# LRFDRFE32 register map
Vendor: Texas Instruments
Peripheral module from a debugger description file (folder CC27xxx10).
Registers are 32-bit, access per field, reset 0x0 unless marked. A register's access mark holds for its fields unless they carry their own. Offsets are as the file gives them; lines under a group give offsets from that group; [hi:lo] are bit positions; {n}, {i} and the like mark numbered series; 'fields as' and 'values as' point back to an identical list; <NAME> marks a mode.

## LRFDRFE32 (part 1 of 2)
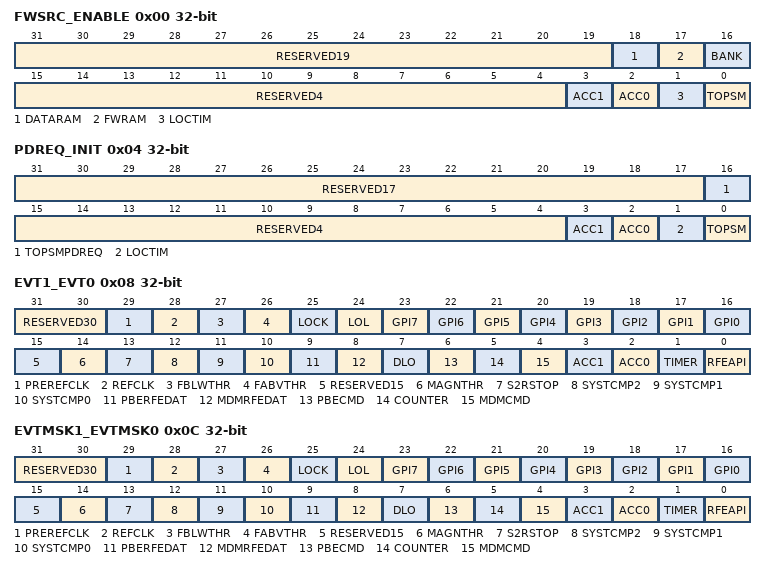
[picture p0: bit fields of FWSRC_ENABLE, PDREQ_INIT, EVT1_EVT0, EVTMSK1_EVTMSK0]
0x00 FWSRC_ENABLE — Internal. Only to be used through TI provided API.
  [31:19] RESERVED19 ro — Internal. Only to be used through TI provided API.
  [18] DATARAM rw — Internal. Only to be used through TI provided API.
    1=S2RRAM (Internal. Only to be used through TI provided API.); 0=RFERAM (Internal. Only to be used through TI provided API.)
  [17] FWRAM rw — Internal. Only to be used through TI provided API.
    values as DATARAM
  [16] BANK rw — Internal. Only to be used through TI provided API.
    1=ONE (Internal. Only to be used through TI provided API.); 0=ZERO (Internal. Only to be used through TI provided API.)
  [15:4] RESERVED4 ro — Internal. Only to be used through TI provided API.
  [3] ACC1 rw — Internal. Only to be used through TI provided API.
    1=EN (Internal. Only to be used through TI provided API.); 0=DIS (Internal. Only to be used through TI provided API.)
  [2] ACC0 rw — Internal. Only to be used through TI provided API.
    values as ACC1
  [1] LOCTIM rw — Internal. Only to be used through TI provided API.
    values as ACC1
  [0] TOPSM rw — Internal. Only to be used through TI provided API.
    values as ACC1
0x04 PDREQ_INIT — Internal. Only to be used through TI provided API.
  [31:17] RESERVED17 ro — Internal. Only to be used through TI provided API.
  [16] TOPSMPDREQ rw — Internal. Only to be used through TI provided API.
    values as FWSRC_ENABLE.BANK
  [15:4] RESERVED4 ro — Internal. Only to be used through TI provided API.
  [3] ACC1 wo — Internal. Only to be used through TI provided API.
    1=RESET (Internal. Only to be used through TI provided API.); 0=NO_EFFECT (Internal. Only to be used through TI provided API.)
  [2] ACC0 wo — Internal. Only to be used through TI provided API.
    values as ACC1
  [1] LOCTIM wo — Internal. Only to be used through TI provided API.
    values as ACC1
  [0] TOPSM wo — Internal. Only to be used through TI provided API.
    values as ACC1
0x08 EVT1_EVT0 ro — Internal. Only to be used through TI provided API.
  [31:30] RESERVED30 — Internal. Only to be used through TI provided API.
  [29] PREREFCLK — Internal. Only to be used through TI provided API.
    values as FWSRC_ENABLE.BANK
  [28] REFCLK — Internal. Only to be used through TI provided API.
    values as FWSRC_ENABLE.BANK
  [27] FBLWTHR — Internal. Only to be used through TI provided API.
    values as FWSRC_ENABLE.BANK
  [26] FABVTHR — Internal. Only to be used through TI provided API.
    values as FWSRC_ENABLE.BANK
  [25] LOCK — Internal. Only to be used through TI provided API.
    values as FWSRC_ENABLE.BANK
  [24] LOL — Internal. Only to be used through TI provided API.
    values as FWSRC_ENABLE.BANK
  [n+16] GPI{n} (n=0..7) — Internal. Only to be used through TI provided API.
    values as FWSRC_ENABLE.BANK
  [15] RESERVED15 — Internal. Only to be used through TI provided API.
  [14] MAGNTHR — Internal. Only to be used through TI provided API.
    values as FWSRC_ENABLE.BANK
  [13] S2RSTOP — Internal. Only to be used through TI provided API.
    values as FWSRC_ENABLE.BANK
  [12] SYSTCMP2 — Internal. Only to be used through TI provided API.
    values as FWSRC_ENABLE.BANK
  [11] SYSTCMP1 — Internal. Only to be used through TI provided API.
    values as FWSRC_ENABLE.BANK
  [10] SYSTCMP0 — Internal. Only to be used through TI provided API.
    values as FWSRC_ENABLE.BANK
  [9] PBERFEDAT — Internal. Only to be used through TI provided API.
    values as FWSRC_ENABLE.BANK
  [8] MDMRFEDAT — Internal. Only to be used through TI provided API.
    values as FWSRC_ENABLE.BANK
  [7] DLO — Internal. Only to be used through TI provided API.
    values as FWSRC_ENABLE.BANK
  [6] PBECMD — Internal. Only to be used through TI provided API.
    values as FWSRC_ENABLE.BANK
  [5] COUNTER — Internal. Only to be used through TI provided API.
    values as FWSRC_ENABLE.BANK
  [4] MDMCMD — Internal. Only to be used through TI provided API.
    values as FWSRC_ENABLE.BANK
  [3] ACC1 — Internal. Only to be used through TI provided API.
    values as FWSRC_ENABLE.BANK
  [2] ACC0 — Internal. Only to be used through TI provided API.
    values as FWSRC_ENABLE.BANK
  [1] TIMER — Internal. Only to be used through TI provided API.
    values as FWSRC_ENABLE.BANK
  [0] RFEAPI — Internal. Only to be used through TI provided API.
    values as FWSRC_ENABLE.BANK
0x0C EVTMSK1_EVTMSK0 — Internal. Only to be used through TI provided API.
  [31:30] RESERVED30 ro — Internal. Only to be used through TI provided API.
  [29] PREREFCLK rw — Internal. Only to be used through TI provided API.
    values as FWSRC_ENABLE.ACC1
  [28] REFCLK rw — Internal. Only to be used through TI provided API.
    values as FWSRC_ENABLE.ACC1
  [27] FBLWTHR rw — Internal. Only to be used through TI provided API.
    values as FWSRC_ENABLE.ACC1
  [26] FABVTHR rw — Internal. Only to be used through TI provided API.
    values as FWSRC_ENABLE.ACC1
  [25] LOCK rw — Internal. Only to be used through TI provided API.
    values as FWSRC_ENABLE.ACC1
  [24] LOL rw — Internal. Only to be used through TI provided API.
    values as FWSRC_ENABLE.ACC1
  [n+16] GPI{n} rw (n=0..7) — Internal. Only to be used through TI provided API.
    values as FWSRC_ENABLE.ACC1
  [15] RESERVED15 ro — Internal. Only to be used through TI provided API.
  [14] MAGNTHR rw — Internal. Only to be used through TI provided API.
    values as FWSRC_ENABLE.ACC1
  [13] S2RSTOP rw — Internal. Only to be used through TI provided API.
    values as FWSRC_ENABLE.ACC1
  [12] SYSTCMP2 rw — Internal. Only to be used through TI provided API.
    values as FWSRC_ENABLE.ACC1
  [11] SYSTCMP1 rw — Internal. Only to be used through TI provided API.
    values as FWSRC_ENABLE.ACC1
  [10] SYSTCMP0 rw — Internal. Only to be used through TI provided API.
    values as FWSRC_ENABLE.ACC1
  [9] PBERFEDAT rw — Internal. Only to be used through TI provided API.
    values as FWSRC_ENABLE.ACC1
  [8] MDMRFEDAT rw — Internal. Only to be used through TI provided API.
    values as FWSRC_ENABLE.ACC1
  [7] DLO rw — Internal. Only to be used through TI provided API.
    values as FWSRC_ENABLE.ACC1
  [6] PBECMD rw — Internal. Only to be used through TI provided API.
    values as FWSRC_ENABLE.ACC1
  [5] COUNTER rw — Internal. Only to be used through TI provided API.
    values as FWSRC_ENABLE.ACC1
  [4] MDMCMD rw — Internal. Only to be used through TI provided API.
    values as FWSRC_ENABLE.ACC1
  [3] ACC1 rw — Internal. Only to be used through TI provided API.
    values as FWSRC_ENABLE.ACC1
  [2] ACC0 rw — Internal. Only to be used through TI provided API.
    values as FWSRC_ENABLE.ACC1
  [1] TIMER rw — Internal. Only to be used through TI provided API.
    values as FWSRC_ENABLE.ACC1
  [0] RFEAPI rw — Internal. Only to be used through TI provided API.
    values as FWSRC_ENABLE.ACC1
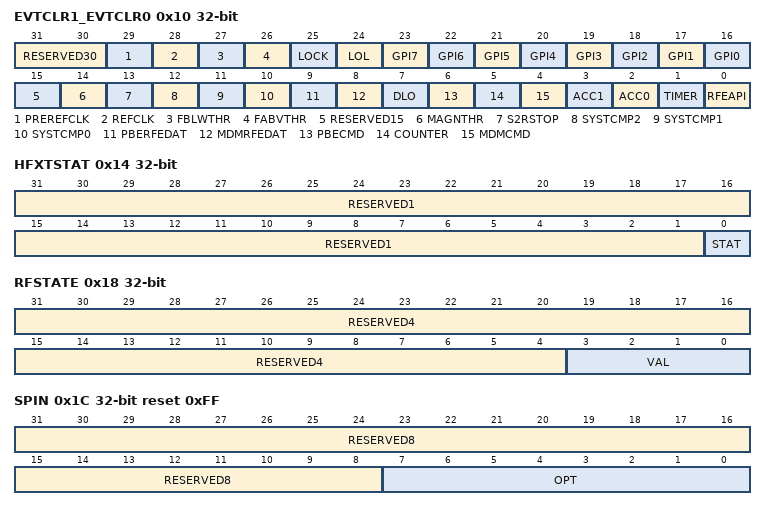
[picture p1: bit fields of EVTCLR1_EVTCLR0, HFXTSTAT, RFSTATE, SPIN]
0x10 EVTCLR1_EVTCLR0 — Internal. Only to be used through TI provided API.
  [31:30] RESERVED30 ro — Internal. Only to be used through TI provided API.
  [29] PREREFCLK wo — Internal. Only to be used through TI provided API.
    values as FWSRC_ENABLE.BANK
  [28] REFCLK wo — Internal. Only to be used through TI provided API.
    values as FWSRC_ENABLE.BANK
  [27] FBLWTHR wo — Internal. Only to be used through TI provided API.
    values as FWSRC_ENABLE.BANK
  [26] FABVTHR wo — Internal. Only to be used through TI provided API.
    values as FWSRC_ENABLE.BANK
  [25] LOCK wo — Internal. Only to be used through TI provided API.
    values as FWSRC_ENABLE.BANK
  [24] LOL wo — Internal. Only to be used through TI provided API.
    values as FWSRC_ENABLE.BANK
  [n+16] GPI{n} wo (n=0..7) — Internal. Only to be used through TI provided API.
    values as FWSRC_ENABLE.BANK
  [15] RESERVED15 ro — Internal. Only to be used through TI provided API.
  [14] MAGNTHR wo — Internal. Only to be used through TI provided API.
    values as FWSRC_ENABLE.BANK
  [13] S2RSTOP wo — Internal. Only to be used through TI provided API.
    values as FWSRC_ENABLE.BANK
  [12] SYSTCMP2 wo — Internal. Only to be used through TI provided API.
    values as FWSRC_ENABLE.BANK
  [11] SYSTCMP1 wo — Internal. Only to be used through TI provided API.
    values as FWSRC_ENABLE.BANK
  [10] SYSTCMP0 wo — Internal. Only to be used through TI provided API.
    values as FWSRC_ENABLE.BANK
  [9] PBERFEDAT wo — Internal. Only to be used through TI provided API.
    values as FWSRC_ENABLE.BANK
  [8] MDMRFEDAT wo — Internal. Only to be used through TI provided API.
    values as FWSRC_ENABLE.BANK
  [7] DLO wo — Internal. Only to be used through TI provided API.
    values as FWSRC_ENABLE.BANK
  [6] PBECMD wo — Internal. Only to be used through TI provided API.
    values as FWSRC_ENABLE.BANK
  [5] COUNTER wo — Internal. Only to be used through TI provided API.
    values as FWSRC_ENABLE.BANK
  [4] MDMCMD wo — Internal. Only to be used through TI provided API.
    values as FWSRC_ENABLE.BANK
  [3] ACC1 wo — Internal. Only to be used through TI provided API.
    values as FWSRC_ENABLE.BANK
  [2] ACC0 wo — Internal. Only to be used through TI provided API.
    values as FWSRC_ENABLE.BANK
  [1] TIMER wo — Internal. Only to be used through TI provided API.
    values as FWSRC_ENABLE.BANK
  [0] RFEAPI wo — Internal. Only to be used through TI provided API.
    values as FWSRC_ENABLE.BANK
0x14 HFXTSTAT ro — Internal. Only to be used through TI provided API.
  [31:1] RESERVED1 — Internal. Only to be used through TI provided API.
  [0] STAT — Internal. Only to be used through TI provided API.
    1=QUAL (Internal. Only to be used through TI provided API.); 0=NONQUAL (Internal. Only to be used through TI provided API.)
0x18 RFSTATE — Internal. Only to be used through TI provided API.
  [31:4] RESERVED4 ro — Internal. Only to be used through TI provided API.
  [3:0] VAL rw — Internal. Only to be used through TI provided API.
    3=RX (Internal. Only to be used through TI provided API.); 2=TX (Internal. Only to be used through TI provided API.); 1=SYNTH (Internal. Only to be used through TI provided API.); 0=IDLE (Internal. Only to be used through TI provided API.)
0x1C SPIN ro reset 0xFF — Internal. Only to be used through TI provided API.
  [31:8] RESERVED8 — Internal. Only to be used through TI provided API.
  [7:0] OPT — Internal. Only to be used through TI provided API.
    255=ALLONES (Internal. Only to be used through TI provided API.); 0=ALLZEROS (Internal. Only to be used through TI provided API.)
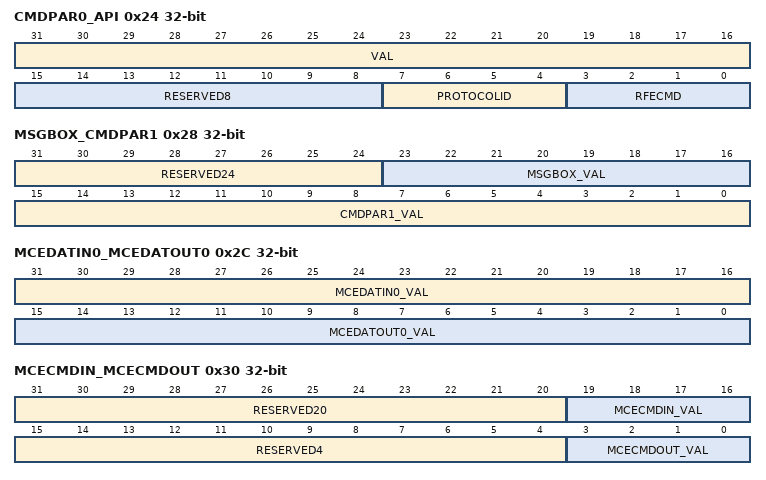
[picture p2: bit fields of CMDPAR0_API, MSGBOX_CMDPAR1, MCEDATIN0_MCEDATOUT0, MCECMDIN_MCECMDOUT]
0x24 CMDPAR0_API ro — Internal. Only to be used through TI provided API.
  [31:16] VAL — Internal. Only to be used through TI provided API.
    0xFFFF=ALLONES (Internal. Only to be used through TI provided API.); 0=ALLZEROS (Internal. Only to be used through TI provided API.)
  [15:8] RESERVED8 — Internal. Only to be used through TI provided API.
  [7:4] PROTOCOLID — Internal. Only to be used through TI provided API.
    15=ALLONES (Internal. Only to be used through TI provided API.); 0=ALLZEROS (Internal. Only to be used through TI provided API.)
  [3:0] RFECMD — Internal. Only to be used through TI provided API.
    values as PROTOCOLID
0x28 MSGBOX_CMDPAR1 — Internal. Only to be used through TI provided API.
  [31:24] RESERVED24 ro — Internal. Only to be used through TI provided API.
  [23:16] MSGBOX_VAL rw — Internal. Only to be used through TI provided API.
    values as SPIN.OPT
  [15:0] CMDPAR1_VAL ro — Internal. Only to be used through TI provided API.
    values as CMDPAR0_API.VAL
0x2C MCEDATIN0_MCEDATOUT0 — Internal. Only to be used through TI provided API.
  [31:16] MCEDATIN0_VAL ro — Internal. Only to be used through TI provided API.
    values as CMDPAR0_API.VAL
  [15:0] MCEDATOUT0_VAL rw — Internal. Only to be used through TI provided API.
    values as CMDPAR0_API.VAL
0x30 MCECMDIN_MCECMDOUT — Internal. Only to be used through TI provided API.
  [31:20] RESERVED20 ro — Internal. Only to be used through TI provided API.
  [19:16] MCECMDIN_VAL ro — Internal. Only to be used through TI provided API.
    values as CMDPAR0_API.PROTOCOLID
  [15:4] RESERVED4 ro — Internal. Only to be used through TI provided API.
  [3:0] MCECMDOUT_VAL rw — Internal. Only to be used through TI provided API.
    values as CMDPAR0_API.PROTOCOLID
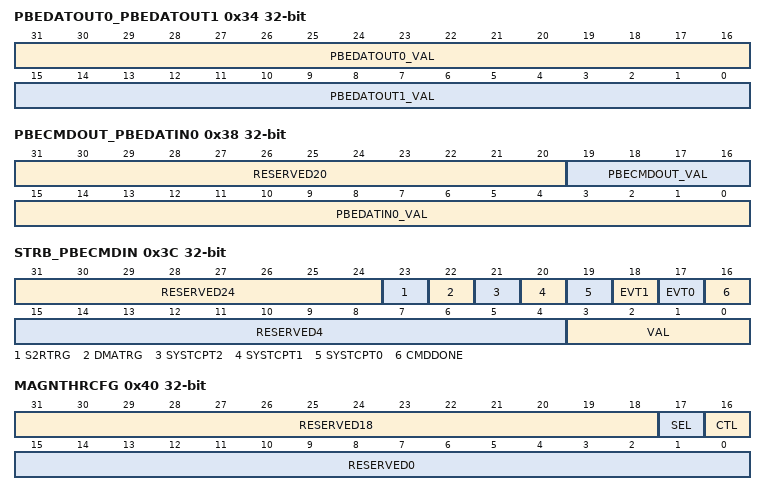
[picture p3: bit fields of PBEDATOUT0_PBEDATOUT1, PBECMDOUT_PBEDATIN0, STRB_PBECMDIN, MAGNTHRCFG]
0x34 PBEDATOUT0_PBEDATOUT1 rw — Internal. Only to be used through TI provided API.
  [31:16] PBEDATOUT0_VAL — Internal. Only to be used through TI provided API.
    values as CMDPAR0_API.VAL
  [15:0] PBEDATOUT1_VAL — Internal. Only to be used through TI provided API.
    values as CMDPAR0_API.VAL
0x38 PBECMDOUT_PBEDATIN0 — Internal. Only to be used through TI provided API.
  [31:20] RESERVED20 ro — Internal. Only to be used through TI provided API.
  [19:16] PBECMDOUT_VAL rw — Internal. Only to be used through TI provided API.
    values as CMDPAR0_API.PROTOCOLID
  [15:0] PBEDATIN0_VAL ro — Internal. Only to be used through TI provided API.
    values as CMDPAR0_API.VAL
0x3C STRB_PBECMDIN — Internal. Only to be used through TI provided API.
  [31:24] RESERVED24 ro — Internal. Only to be used through TI provided API.
  [23] S2RTRG wo — Internal. Only to be used through TI provided API.
    values as FWSRC_ENABLE.BANK
  [22] DMATRG wo — Internal. Only to be used through TI provided API.
    values as FWSRC_ENABLE.BANK
  [21] SYSTCPT2 wo — Internal. Only to be used through TI provided API.
    values as FWSRC_ENABLE.BANK
  [20] SYSTCPT1 wo — Internal. Only to be used through TI provided API.
    values as FWSRC_ENABLE.BANK
  [19] SYSTCPT0 wo — Internal. Only to be used through TI provided API.
    values as FWSRC_ENABLE.BANK
  [18] EVT1 wo — Internal. Only to be used through TI provided API.
    values as FWSRC_ENABLE.BANK
  [17] EVT0 wo — Internal. Only to be used through TI provided API.
    values as FWSRC_ENABLE.BANK
  [16] CMDDONE wo — Internal. Only to be used through TI provided API.
    1=YES (Internal. Only to be used through TI provided API.); 0=NO (Internal. Only to be used through TI provided API.)
  [15:4] RESERVED4 ro — Internal. Only to be used through TI provided API.
  [3:0] VAL ro — Internal. Only to be used through TI provided API.
    values as CMDPAR0_API.PROTOCOLID
0x40 MAGNTHRCFG — Internal. Only to be used through TI provided API.
  [31:18] RESERVED18 ro — Internal. Only to be used through TI provided API.
  [17] SEL rw — Internal. Only to be used through TI provided API.
    1=MAGNACC1 (Internal. Only to be used through TI provided API.); 0=MAGNACC0 (Internal. Only to be used through TI provided API.)
  [16] CTL rw — Internal. Only to be used through TI provided API.
    values as FWSRC_ENABLE.ACC1
  [15:0] RESERVED0 ro — Internal. Only to be used through TI provided API.
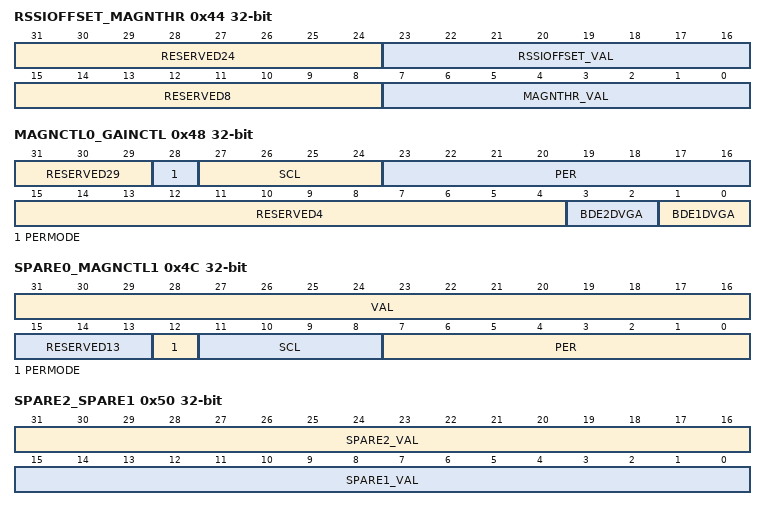
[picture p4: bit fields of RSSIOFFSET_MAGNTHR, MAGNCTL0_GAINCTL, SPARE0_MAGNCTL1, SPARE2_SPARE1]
0x44 RSSIOFFSET_MAGNTHR — Internal. Only to be used through TI provided API.
  [31:24] RESERVED24 ro — Internal. Only to be used through TI provided API.
  [23:16] RSSIOFFSET_VAL rw — Internal. Only to be used through TI provided API.
    values as SPIN.OPT
  [15:8] RESERVED8 ro — Internal. Only to be used through TI provided API.
  [7:0] MAGNTHR_VAL rw — Internal. Only to be used through TI provided API.
    values as SPIN.OPT
0x48 MAGNCTL0_GAINCTL — Internal. Only to be used through TI provided API.
  [31:29] RESERVED29 ro — Internal. Only to be used through TI provided API.
  [28] PERMODE rw — Internal. Only to be used through TI provided API.
    1=PERIODIC (Internal. Only to be used through TI provided API.); 0=ONESHOT (Internal. Only to be used through TI provided API.)
  [27:24] SCL rw — Internal. Only to be used through TI provided API.
    8=DIV256 (Internal. Only to be used through TI provided API.); 7=DIV128 (Internal. Only to be used through TI provided API.); 6=DIV64 (Internal. Only to be used through TI provided API.); 5=DIV32 (Internal. Only to be used through TI provided API.); 4=DIV16 (Internal. Only to be used through TI provided API.); 3=DIV8 (Internal. Only to be used through TI provided API.); 2=DIV4 (Internal. Only to be used through TI provided API.); 1=DIV2 (Internal. Only to be used through TI provided API.); 0=DIV1 (Internal. Only to be used through TI provided API.)
  [23:16] PER rw — Internal. Only to be used through TI provided API.
    values as SPIN.OPT
  [15:4] RESERVED4 ro — Internal. Only to be used through TI provided API.
  [3:2] BDE2DVGA rw — Internal. Only to be used through TI provided API.
    3=GAIN8 (Internal. Only to be used through TI provided API.); 2=GAIN4 (Internal. Only to be used through TI provided API.); 1=GAIN2 (Internal. Only to be used through TI provided API.); 0=GAIN1 (Internal. Only to be used through TI provided API.)
  [1:0] BDE1DVGA rw — Internal. Only to be used through TI provided API.
    values as BDE2DVGA
0x4C SPARE0_MAGNCTL1 — Internal. Only to be used through TI provided API.
  [31:16] VAL rw — Internal. Only to be used through TI provided API.
    values as CMDPAR0_API.VAL
  [15:13] RESERVED13 ro — Internal. Only to be used through TI provided API.
  [12] PERMODE rw — Internal. Only to be used through TI provided API.
    values as MAGNCTL0_GAINCTL.PERMODE
  [11:8] SCL rw — Internal. Only to be used through TI provided API.
    values as MAGNCTL0_GAINCTL.SCL
  [7:0] PER rw — Internal. Only to be used through TI provided API.
    values as SPIN.OPT
0x50 SPARE2_SPARE1 rw — Internal. Only to be used through TI provided API.
  [31:16] SPARE2_VAL — Internal. Only to be used through TI provided API.
    values as CMDPAR0_API.VAL
  [15:0] SPARE1_VAL — Internal. Only to be used through TI provided API.
    values as CMDPAR0_API.VAL
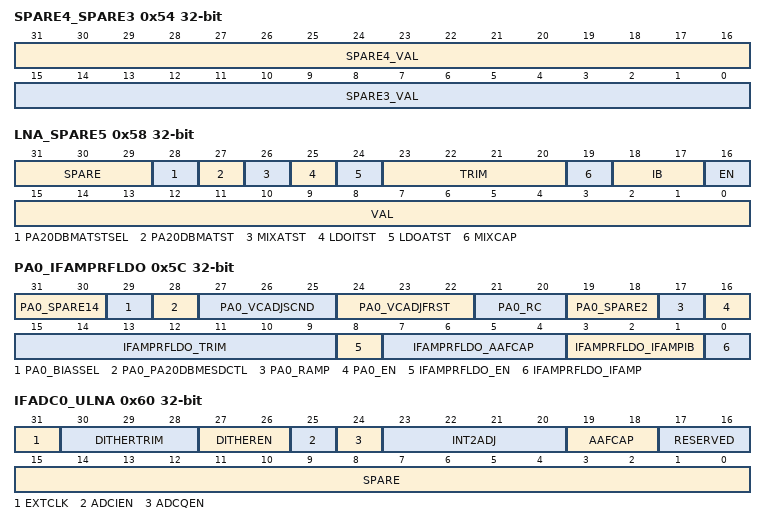
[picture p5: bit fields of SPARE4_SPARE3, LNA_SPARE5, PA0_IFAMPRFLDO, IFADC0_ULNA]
0x54 SPARE4_SPARE3 rw — Internal. Only to be used through TI provided API.
  [31:16] SPARE4_VAL — Internal. Only to be used through TI provided API.
    values as CMDPAR0_API.VAL
  [15:0] SPARE3_VAL — Internal. Only to be used through TI provided API.
    values as CMDPAR0_API.VAL
0x58 LNA_SPARE5 rw — Internal. Only to be used through TI provided API.
  [31:29] SPARE — Internal. Only to be used through TI provided API.
    values as FWSRC_ENABLE.ACC1
  [28] PA20DBMATSTSEL — Internal. Only to be used through TI provided API.
    1=SECOND (Internal. Only to be used through TI provided API.); 0=FIRST (Internal. Only to be used through TI provided API.)
  [27] PA20DBMATST — Internal. Only to be used through TI provided API.
    values as FWSRC_ENABLE.ACC1
  [26] MIXATST — Internal. Only to be used through TI provided API.
    values as FWSRC_ENABLE.ACC1
  [25] LDOITST — Internal. Only to be used through TI provided API.
    values as FWSRC_ENABLE.ACC1
  [24] LDOATST — Internal. Only to be used through TI provided API.
    values as FWSRC_ENABLE.ACC1
  [23:20] TRIM — Internal. Only to be used through TI provided API.
    15=ONES (Internal. Only to be used through TI provided API.); 0=ZEROS (Internal. Only to be used through TI provided API.)
  [19] MIXCAP — Internal. Only to be used through TI provided API.
    values as FWSRC_ENABLE.ACC1
  [18:17] IB — Internal. Only to be used through TI provided API.
    3=MAX (Internal. Only to be used through TI provided API.); 0=MIN (Internal. Only to be used through TI provided API.)
  [16] EN — Internal. Only to be used through TI provided API.
    1=ON (Internal. Only to be used through TI provided API.); 0=OFF (Internal. Only to be used through TI provided API.)
  [15:0] VAL — Internal. Only to be used through TI provided API.
    values as CMDPAR0_API.VAL
0x5C PA0_IFAMPRFLDO rw — Internal. Only to be used through TI provided API.
  [31:30] PA0_SPARE14 — Internal. Only to be used through TI provided API.
    values as LNA_SPARE5.IB
  [29] PA0_BIASSEL — Internal. Only to be used through TI provided API.
    values as FWSRC_ENABLE.BANK
  [28] PA0_PA20DBMESDCTL — Internal. Only to be used through TI provided API.
    values as FWSRC_ENABLE.BANK
  [27:25] PA0_VCADJSCND — Internal. Only to be used through TI provided API.
    7=MAX (Internal. Only to be used through TI provided API.); 0=MIN (Internal. Only to be used through TI provided API.)
  [24:22] PA0_VCADJFRST — Internal. Only to be used through TI provided API.
    values as PA0_VCADJSCND
  [21:20] PA0_RC — Internal. Only to be used through TI provided API.
    values as LNA_SPARE5.IB
  [19:18] PA0_SPARE2 — Internal. Only to be used through TI provided API.
    values as LNA_SPARE5.IB
  [17] PA0_RAMP — Internal. Only to be used through TI provided API.
    1=UP (Internal. Only to be used through TI provided API.); 0=DOWN (Internal. Only to be used through TI provided API.)
  [16] PA0_EN — Internal. Only to be used through TI provided API.
    values as FWSRC_ENABLE.ACC1
  [15:9] IFAMPRFLDO_TRIM — Internal. Only to be used through TI provided API.
    127=BYPASS (Internal. Only to be used through TI provided API.); 126=MAX (Internal. Only to be used through TI provided API.); 0=MIN (Internal. Only to be used through TI provided API.)
  [8] IFAMPRFLDO_EN — Internal. Only to be used through TI provided API.
    values as FWSRC_ENABLE.ACC1
  [7:4] IFAMPRFLDO_AAFCAP — Internal. Only to be used through TI provided API.
    15=MAX (Internal. Only to be used through TI provided API.); 0=MIN (Internal. Only to be used through TI provided API.)
  [3:1] IFAMPRFLDO_IFAMPIB — Internal. Only to be used through TI provided API.
    values as PA0_VCADJSCND
  [0] IFAMPRFLDO_IFAMP — Internal. Only to be used through TI provided API.
    values as FWSRC_ENABLE.ACC1
0x60 IFADC0_ULNA rw — Internal. Only to be used through TI provided API.
  [31] EXTCLK — Internal. Only to be used through TI provided API.
    values as FWSRC_ENABLE.ACC1
  [30:28] DITHERTRIM — Internal. Only to be used through TI provided API.
    7=ONES (Internal. Only to be used through TI provided API.); 0=ZEROS (Internal. Only to be used through TI provided API.)
  [27:26] DITHEREN — Internal. Only to be used through TI provided API.
    3=ENG (Internal. Only to be used through TI provided API.); 2=ENSD (Internal. Only to be used through TI provided API.); 1=ENS (Internal. Only to be used through TI provided API.); 0=DIS (Internal. Only to be used through TI provided API.)
  [25] ADCIEN — Internal. Only to be used through TI provided API.
    values as FWSRC_ENABLE.ACC1
  [24] ADCQEN — Internal. Only to be used through TI provided API.
    values as FWSRC_ENABLE.ACC1
  [23:20] INT2ADJ — Internal. Only to be used through TI provided API.
    values as LNA_SPARE5.TRIM
  [19:18] AAFCAP — Internal. Only to be used through TI provided API.
    values as DITHEREN
  [17:16] RESERVED — Internal. Only to be used through TI provided API.
    3=ONES (Internal. Only to be used through TI provided API.); 0=ZEROS (Internal. Only to be used through TI provided API.)
  [15:0] SPARE — Internal. Only to be used through TI provided API.
    values as CMDPAR0_API.VAL
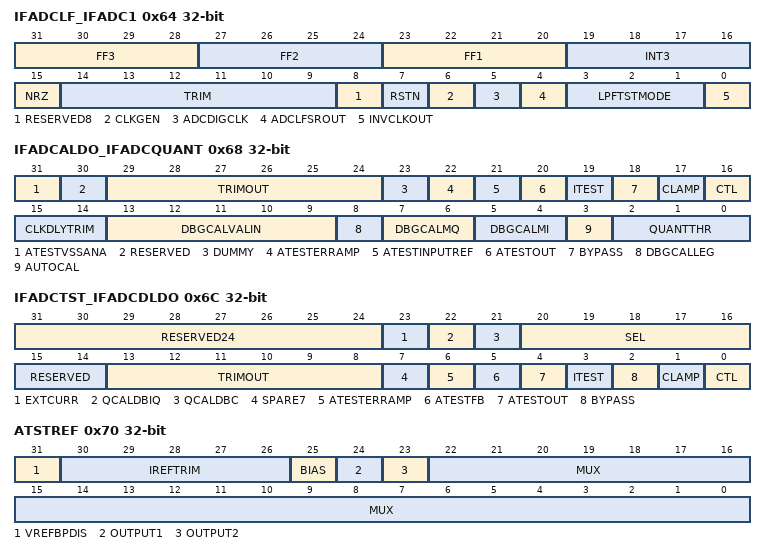
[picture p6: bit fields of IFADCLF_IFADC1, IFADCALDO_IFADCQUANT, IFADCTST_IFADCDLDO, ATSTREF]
0x64 IFADCLF_IFADC1 rw — Internal. Only to be used through TI provided API.
  [31:28] FF3 — Internal. Only to be used through TI provided API.
    values as LNA_SPARE5.TRIM
  [27:24] FF2 — Internal. Only to be used through TI provided API.
    values as LNA_SPARE5.TRIM
  [23:20] FF1 — Internal. Only to be used through TI provided API.
    values as LNA_SPARE5.TRIM
  [19:16] INT3 — Internal. Only to be used through TI provided API.
    values as LNA_SPARE5.TRIM
  [15] NRZ — Internal. Only to be used through TI provided API.
    values as FWSRC_ENABLE.ACC1
  [14:9] TRIM — Internal. Only to be used through TI provided API.
    63=ONES (Internal. Only to be used through TI provided API.); 0=ZEROS (Internal. Only to be used through TI provided API.)
  [8] RESERVED8 — Internal. Only to be used through TI provided API.
    values as FWSRC_ENABLE.ACC1
  [7] RSTN — Internal. Only to be used through TI provided API.
    1=DIS (Internal. Only to be used through TI provided API.); 0=EN (Internal. Only to be used through TI provided API.)
  [6] CLKGEN — Internal. Only to be used through TI provided API.
    values as FWSRC_ENABLE.ACC1
  [5] ADCDIGCLK — Internal. Only to be used through TI provided API.
    values as FWSRC_ENABLE.ACC1
  [4] ADCLFSROUT — Internal. Only to be used through TI provided API.
    values as FWSRC_ENABLE.ACC1
  [3:1] LPFTSTMODE — Internal. Only to be used through TI provided API.
    values as FWSRC_ENABLE.ACC1
  [0] INVCLKOUT — Internal. Only to be used through TI provided API.
    values as FWSRC_ENABLE.ACC1
0x68 IFADCALDO_IFADCQUANT rw — Internal. Only to be used through TI provided API.
  [31] ATESTVSSANA — Internal. Only to be used through TI provided API.
    values as FWSRC_ENABLE.ACC1
  [30] RESERVED — Internal. Only to be used through TI provided API.
    1=ONES (Internal. Only to be used through TI provided API.); 0=ZEROS (Internal. Only to be used through TI provided API.)
  [29:24] TRIMOUT — Internal. Only to be used through TI provided API.
    values as IFADCLF_IFADC1.TRIM
  [23] DUMMY — Internal. Only to be used through TI provided API.
    1=DISN (Internal. Only to be used through TI provided API.); 0=ENN (Internal. Only to be used through TI provided API.)
  [22] ATESTERRAMP — Internal. Only to be used through TI provided API.
    values as FWSRC_ENABLE.ACC1
  [21] ATESTINPUTREF — Internal. Only to be used through TI provided API.
    values as FWSRC_ENABLE.ACC1
  [20] ATESTOUT — Internal. Only to be used through TI provided API.
    values as FWSRC_ENABLE.ACC1
  [19] ITEST — Internal. Only to be used through TI provided API.
    values as FWSRC_ENABLE.ACC1
  [18] BYPASS — Internal. Only to be used through TI provided API.
    values as FWSRC_ENABLE.ACC1
  [17] CLAMP — Internal. Only to be used through TI provided API.
    values as FWSRC_ENABLE.ACC1
  [16] CTL — Internal. Only to be used through TI provided API.
    values as FWSRC_ENABLE.ACC1
  [15:14] CLKDLYTRIM — Internal. Only to be used through TI provided API.
    values as IFADC0_ULNA.RESERVED
  [13:9] DBGCALVALIN — Internal. Only to be used through TI provided API.
    31=ONES (Internal. Only to be used through TI provided API.); 0=ZEROS (Internal. Only to be used through TI provided API.)
  [8] DBGCALLEG — Internal. Only to be used through TI provided API.
    1=NEG (Internal. Only to be used through TI provided API.); 0=POS (Internal. Only to be used through TI provided API.)
  [7:6] DBGCALMQ — Internal. Only to be used through TI provided API.
    3=DBGCAL_QMODB (Internal. Only to be used through TI provided API.); 2=DBGCAL_QMODP (Internal. Only to be used through TI provided API.); 1=DBGCAL_QMODN (Internal. Only to be used through TI provided API.); 0=DBGCAL_QMODZ (Internal. Only to be used through TI provided API.)
  [5:4] DBGCALMI — Internal. Only to be used through TI provided API.
    3=DBGCAL_IMODB (Internal. Only to be used through TI provided API.); 2=DBGCAL_IMODP (Internal. Only to be used through TI provided API.); 1=DBGCAL_IMODN (Internal. Only to be used through TI provided API.); 0=DBGCAL_IMODZ (Internal. Only to be used through TI provided API.)
  [3] AUTOCAL — Internal. Only to be used through TI provided API.
    values as FWSRC_ENABLE.ACC1
  [2:0] QUANTTHR — Internal. Only to be used through TI provided API.
    values as IFADC0_ULNA.DITHERTRIM
0x6C IFADCTST_IFADCDLDO — Internal. Only to be used through TI provided API.
  [31:24] RESERVED24 ro — Internal. Only to be used through TI provided API.
  [23] EXTCURR rw — Internal. Only to be used through TI provided API.
    values as FWSRC_ENABLE.ACC1
  [22] QCALDBIQ rw — Internal. Only to be used through TI provided API.
    1=COMP1 (Internal. Only to be used through TI provided API.); 0=COMP0 (Internal. Only to be used through TI provided API.)
  [21] QCALDBC rw — Internal. Only to be used through TI provided API.
    values as QCALDBIQ
  [20:16] SEL rw — Internal. Only to be used through TI provided API.
    31=EXTCLKN1 (Internal. Only to be used through TI provided API.); 0=NONE (Internal. Only to be used through TI provided API.)
  [15:14] RESERVED rw — Internal. Only to be used through TI provided API.
    values as IFADC0_ULNA.RESERVED
  [13:8] TRIMOUT rw — Internal. Only to be used through TI provided API.
    values as IFADCLF_IFADC1.TRIM
  [7] SPARE7 rw — Internal. Only to be used through TI provided API.
    1=One (Internal. Only to be used through TI provided API.); 0=ZERO (Internal. Only to be used through TI provided API.)
  [6] ATESTERRAMP rw — Internal. Only to be used through TI provided API.
    values as FWSRC_ENABLE.ACC1
  [5] ATESTFB rw — Internal. Only to be used through TI provided API.
    values as FWSRC_ENABLE.ACC1
  [4] ATESTOUT rw — Internal. Only to be used through TI provided API.
    values as FWSRC_ENABLE.ACC1
  [3] ITEST rw — Internal. Only to be used through TI provided API.
    values as FWSRC_ENABLE.ACC1
  [2] BYPASS rw — Internal. Only to be used through TI provided API.
    values as FWSRC_ENABLE.ACC1
  [1] CLAMP rw — Internal. Only to be used through TI provided API.
    values as FWSRC_ENABLE.ACC1
  [0] CTL rw — Internal. Only to be used through TI provided API.
    values as FWSRC_ENABLE.ACC1
0x70 ATSTREF rw — Internal. Only to be used through TI provided API.
  [31] VREFBPDIS — Internal. Only to be used through TI provided API.
    1=BPDIS (Internal. Only to be used through TI provided API.); 0=BPEN (Internal. Only to be used through TI provided API.)
  [30:26] IREFTRIM — Internal. Only to be used through TI provided API.
    values as IFADCALDO_IFADCQUANT.DBGCALVALIN
  [25] BIAS — Internal. Only to be used through TI provided API.
    values as FWSRC_ENABLE.ACC1
  [24] OUTPUT1 — Internal. Only to be used through TI provided API.
    values as FWSRC_ENABLE.ACC1
  [23] OUTPUT2 — Internal. Only to be used through TI provided API.
    values as FWSRC_ENABLE.ACC1
  [22:0] MUX — Internal. Only to be used through TI provided API.
    0x8000=IFADC_ATB (Internal. Only to be used through TI provided API.); 0x4000=LDO_VTEST (Internal. Only to be used through TI provided API.); 0x2000=LDO_ITEST (Internal. Only to be used through TI provided API.); 0x800=PA_PEAK_OUTN (Internal. Only to be used through TI provided API.); 0x400=PA_PEAK_OUTP (Internal. Only to be used through TI provided API.); 0x200=MIX_OUTQN (Internal. Only to be used through TI provided API.); 0x100=MIX_OUTQP (Internal. Only to be used through TI provided API.); 128=MIX_OUTIN (Internal. Only to be used through TI provided API.); 64=MIX_OUTIP (Internal. Only to be used through TI provided API.); 32=FE_OUTIN_2 (Internal. Only to be used through TI provided API.); 16=FE_OUTIP_2 (Internal. Only to be used through TI provided API.); 8=FE_OUTQN (Internal. Only to be used through TI provided API.); 4=FE_OUTQP (Internal. Only to be used through TI provided API.); 2=FE_OUTIN (Internal. Only to be used through TI provided API.); 1=FE_OUTIP (Internal. Only to be used through TI provided API.); 0=DIS (Internal. Only to be used through TI provided API.)
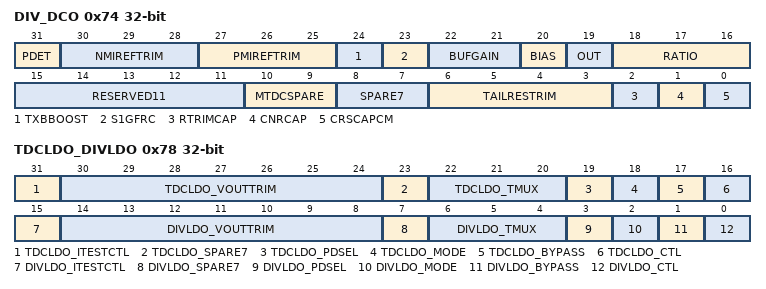
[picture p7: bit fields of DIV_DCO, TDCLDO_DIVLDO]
0x74 DIV_DCO — Internal. Only to be used through TI provided API.
  [31] PDET rw — Internal. Only to be used through TI provided API.
    values as FWSRC_ENABLE.ACC1
  [30:28] NMIREFTRIM rw — Internal. Only to be used through TI provided API.
    7=ALLONES (Internal. Only to be used through TI provided API.); 0=ALLZEROS (Internal. Only to be used through TI provided API.)
  [27:25] PMIREFTRIM rw — Internal. Only to be used through TI provided API.
    values as NMIREFTRIM
  [24] TXBBOOST rw — Internal. Only to be used through TI provided API.
    1=INCREASED (Internal. Only to be used through TI provided API.); 0=DEFAULT (Internal. Only to be used through TI provided API.)
  [23] S1GFRC rw — Internal. Only to be used through TI provided API.
    values as FWSRC_ENABLE.ACC1
  [22:21] BUFGAIN rw — Internal. Only to be used through TI provided API.
    3=_60_PST (Internal. Only to be used through TI provided API.); 2=DONT_USE (Internal. Only to be used through TI provided API.); 1=_80_PST (Internal. Only to be used through TI provided API.); 0=MAX (Internal. Only to be used through TI provided API.)
  [20] BIAS rw — Internal. Only to be used through TI provided API.
    1=DEFAULT (Internal. Only to be used through TI provided API.); 0=ALTERNATIVE (Internal. Only to be used through TI provided API.)
  [19] OUT rw — Internal. Only to be used through TI provided API.
    1=FE_2G4 (Internal. Only to be used through TI provided API.); 0=FE_S1G (Internal. Only to be used through TI provided API.)
  [18:16] RATIO rw — Internal. Only to be used through TI provided API.
    7=DIV30 (Internal. Only to be used through TI provided API.); 6=DIV15 (Internal. Only to be used through TI provided API.); 5=DIV10 (Internal. Only to be used through TI provided API.); 4=DIV5 (Internal. Only to be used through TI provided API.); 3=DIV12 (Internal. Only to be used through TI provided API.); 2=DIV6 (Internal. Only to be used through TI provided API.); 1=DIV4 (Internal. Only to be used through TI provided API.); 0=DIV2 (Internal. Only to be used through TI provided API.)
  [15:11] RESERVED11 ro — Internal. Only to be used through TI provided API.
  [10:9] MTDCSPARE rw — Internal. Only to be used through TI provided API.
    values as IFADCLF_IFADC1.RSTN
  [8:7] SPARE7 rw — Internal. Only to be used through TI provided API.
    values as FWSRC_ENABLE.BANK
  [6:3] TAILRESTRIM rw — Internal. Only to be used through TI provided API.
    values as CMDPAR0_API.PROTOCOLID
  [2] RTRIMCAP rw — Internal. Only to be used through TI provided API.
    values as FWSRC_ENABLE.ACC1
  [1] CNRCAP rw — Internal. Only to be used through TI provided API.
    1=_50MHZ (Internal. Only to be used through TI provided API.); 0=DEFAULT (Internal. Only to be used through TI provided API.)
  [0] CRSCAPCM rw — Internal. Only to be used through TI provided API.
    1=REDUCED (Internal. Only to be used through TI provided API.); 0=DEFAULT (Internal. Only to be used through TI provided API.)
0x78 TDCLDO_DIVLDO rw — Internal. Only to be used through TI provided API.
  [31] TDCLDO_ITESTCTL — Internal. Only to be used through TI provided API.
    values as FWSRC_ENABLE.ACC1
  [30:24] TDCLDO_VOUTTRIM — Internal. Only to be used through TI provided API.
    127=ONES (Internal. Only to be used through TI provided API.); 0=ZEROS (Internal. Only to be used through TI provided API.)
  [23] TDCLDO_SPARE7 — Internal. Only to be used through TI provided API.
    values as IFADCTST_IFADCDLDO.SPARE7
  [22:20] TDCLDO_TMUX — Internal. Only to be used through TI provided API.
    4=VSSR (Internal. Only to be used through TI provided API.); 2=LDO_OUT (Internal. Only to be used through TI provided API.); 1=VDDR (Internal. Only to be used through TI provided API.); 0=OFF (Internal. Only to be used through TI provided API.)
  [19] TDCLDO_PDSEL — Internal. Only to be used through TI provided API.
    1=DIODE (Internal. Only to be used through TI provided API.); 0=R (Internal. Only to be used through TI provided API.)
  [18] TDCLDO_MODE — Internal. Only to be used through TI provided API.
    1=FAST (Internal. Only to be used through TI provided API.); 0=NORM (Internal. Only to be used through TI provided API.)
  [17] TDCLDO_BYPASS — Internal. Only to be used through TI provided API.
    values as FWSRC_ENABLE.ACC1
  [16] TDCLDO_CTL — Internal. Only to be used through TI provided API.
    values as FWSRC_ENABLE.ACC1
  [15] DIVLDO_ITESTCTL — Internal. Only to be used through TI provided API.
    values as FWSRC_ENABLE.ACC1
  [14:8] DIVLDO_VOUTTRIM — Internal. Only to be used through TI provided API.
    values as TDCLDO_VOUTTRIM
  [7] DIVLDO_SPARE7 — Internal. Only to be used through TI provided API.
    1=ONE (Internal. Only to be used through TI provided API.); 0=Zero (Internal. Only to be used through TI provided API.)
  [6:4] DIVLDO_TMUX — Internal. Only to be used through TI provided API.
    values as TDCLDO_TMUX
  [3] DIVLDO_PDSEL — Internal. Only to be used through TI provided API.
    values as TDCLDO_PDSEL
  [2] DIVLDO_MODE — Internal. Only to be used through TI provided API.
    values as TDCLDO_MODE
  [1] DIVLDO_BYPASS — Internal. Only to be used through TI provided API.
    values as FWSRC_ENABLE.ACC1
  [0] DIVLDO_CTL — Internal. Only to be used through TI provided API.
    values as FWSRC_ENABLE.ACC1
